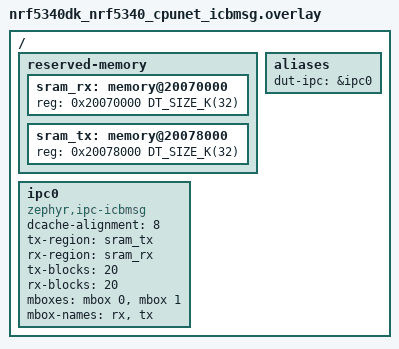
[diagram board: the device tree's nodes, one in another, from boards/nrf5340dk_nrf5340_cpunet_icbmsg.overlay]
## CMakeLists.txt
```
#
# Copyright (c) 2026 Nordic Semiconductor ASA
#
# SPDX-License-Identifier: Apache-2.0
#

cmake_minimum_required(VERSION 3.28.0)

find_package(Zephyr REQUIRED HINTS $ENV{ZEPHYR_BASE})
project(ipc_service_api_remote)

target_include_directories(app PRIVATE ${CMAKE_CURRENT_SOURCE_DIR}/../common)
target_sources(app PRIVATE src/remote.c)
```

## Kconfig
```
# Copyright (c) 2026 Nordic Semiconductor ASA
# SPDX-License-Identifier: Apache-2.0

rsource "../Kconfig"
```

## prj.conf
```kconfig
CONFIG_IPC_SERVICE=y
CONFIG_MBOX=y
CONFIG_LOG=y
```

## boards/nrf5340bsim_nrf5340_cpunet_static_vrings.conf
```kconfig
CONFIG_HEAP_MEM_POOL_SIZE=4096
CONFIG_OPENAMP=y
CONFIG_OPENAMP_MASTER=n
```

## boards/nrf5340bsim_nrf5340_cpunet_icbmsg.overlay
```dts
/*
 * Copyright (c) 2026 Nordic Semiconductor ASA
 *
 * SPDX-License-Identifier: Apache-2.0
 */

#include "nrf5340dk_nrf5340_cpunet_icbmsg.overlay"
```

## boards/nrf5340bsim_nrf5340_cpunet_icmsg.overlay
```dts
/*
 * Copyright (c) 2026 Nordic Semiconductor ASA
 *
 * SPDX-License-Identifier: Apache-2.0
 */

#include "nrf5340dk_nrf5340_cpunet_icmsg.overlay"
```

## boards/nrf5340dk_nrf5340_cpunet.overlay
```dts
/*
 * Copyright (c) 2026 Nordic Semiconductor ASA
 *
 * SPDX-License-Identifier: Apache-2.0
 */

#include "nrf5340dk_nrf5340_cpunet_common.dtsi"
```

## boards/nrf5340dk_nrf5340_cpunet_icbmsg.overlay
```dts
/*
 * Copyright (c) 2026 Nordic Semiconductor ASA
 *
 * SPDX-License-Identifier: Apache-2.0
 */

#include "nrf5340dk_nrf5340_cpunet_common.dtsi"

/ {
	reserved-memory {
		ranges;
		#address-cells = <1>;
		#size-cells = <1>;

		sram_rx: memory@20070000 {
			reg = <0x20070000 DT_SIZE_K(32)>;
		};

		sram_tx: memory@20078000 {
			reg = <0x20078000 DT_SIZE_K(32)>;
		};
	};

	ipc0: ipc0 {
		compatible = "zephyr,ipc-icbmsg";
		dcache-alignment = <8>;
		tx-region = <&sram_tx>;
		rx-region = <&sram_rx>;
		tx-blocks = <20>;
		rx-blocks = <20>;
		mboxes = <&mbox 0>, <&mbox 1>;
		mbox-names = "rx", "tx";
		status = "okay";
	};

	aliases {
		dut-ipc = &ipc0;
	};
};
```

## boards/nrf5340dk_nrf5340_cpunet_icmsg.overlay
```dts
/*
 * Copyright (c) 2026 Nordic Semiconductor ASA
 *
 * SPDX-License-Identifier: Apache-2.0
 */

#include "nrf5340dk_nrf5340_cpunet_common.dtsi"

/ {
	reserved-memory {
		ranges;
		#address-cells = <1>;
		#size-cells = <1>;

		sram_rx: memory@20070000 {
			reg = <0x20070000 DT_SIZE_K(32)>;
		};

		sram_tx: memory@20078000 {
			reg = <0x20078000 DT_SIZE_K(32)>;
		};
	};

	ipc0: ipc0 {
		compatible = "zephyr,ipc-icmsg";
		dcache-alignment = <8>;
		tx-region = <&sram_tx>;
		rx-region = <&sram_rx>;
		mboxes = <&mbox 0>, <&mbox 1>;
		mbox-names = "rx", "tx";
		status = "okay";
	};

	aliases {
		dut-ipc = &ipc0;
	};
};
```

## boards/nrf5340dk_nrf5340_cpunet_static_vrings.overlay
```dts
/*
 * Copyright (c) 2026 Nordic Semiconductor ASA
 *
 * SPDX-License-Identifier: Apache-2.0
 */

#include "nrf5340dk_nrf5340_cpunet_common.dtsi"
#include <zephyr/dt-bindings/ipc_service/static_vrings.h>

/ {
	reserved-memory {
		#address-cells = <1>;
		#size-cells = <1>;

		sram_ipc0: memory@20070000 {
			reg = <0x20070000 DT_SIZE_K(8)>;
		};
	};

	ipc0: ipc0 {
		compatible = "zephyr,ipc-openamp-static-vrings";
		memory-region = <&sram_ipc0>;
		mboxes = <&mbox 0>, <&mbox 1>;
		mbox-names = "rx", "tx";
		role = "remote";
		zephyr,buffer-size = <128>;
		status = "okay";
	};

	aliases {
		dut-ipc = &ipc0;
	};
};
```

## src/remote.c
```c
/*
 * Copyright (c) 2026 Nordic Semiconductor ASA
 *
 * SPDX-License-Identifier: Apache-2.0
 */

#include <string.h>

#include <zephyr/kernel.h>
#include <zephyr/device.h>
#include <zephyr/ipc/ipc_service.h>

#include <test_context.h>

#include <zephyr/logging/log.h>
LOG_MODULE_REGISTER(remote, LOG_LEVEL_INF);

#if DT_HAS_ALIAS(dut_ipc)
#define IPC_NODE DT_ALIAS(dut_ipc)
#elif DT_NUM_INST_STATUS_OKAY(zephyr_ipc_icbmsg) == 1
#define IPC_NODE DT_COMPAT_GET_ANY_STATUS_OKAY(zephyr_ipc_icbmsg)
#elif DT_NUM_INST_STATUS_OKAY(zephyr_ipc_icmsg) == 1
#define IPC_NODE DT_COMPAT_GET_ANY_STATUS_OKAY(zephyr_ipc_icmsg)
#elif DT_NUM_INST_STATUS_OKAY(zephyr_ipc_openamp_static_vrings) == 1
#define IPC_NODE DT_COMPAT_GET_ANY_STATUS_OKAY(zephyr_ipc_openamp_static_vrings)
#else
#error "No IPC node found"
#endif

static struct test_context test_ctx[TEST_EP_COUNT];
static const char *ep_name[TEST_EP_COUNT] = {"ep0", "ep1"};

static const struct device *ipc_instance = DEVICE_DT_GET(IPC_NODE);
static volatile bool close_after_unbound;

static volatile bool reregister_request;

static struct test_context *ep0(void)
{
	return &test_ctx[TEST_EP0];
}

static void reregister_action(struct test_context *ctx)
{
	int ret;

	ret = ipc_service_deregister_endpoint(&ctx->ep);
	if (ret < 0 && ret != -ENOENT) {
		LOG_ERR("ipc_service_deregister_endpoint() failed: %d", ret);
	}

	k_msleep(10);

	ret = ipc_service_register_endpoint(ipc_instance, &ctx->ep, &ctx->ep_cfg);
	if (ret < 0) {
		LOG_ERR("ipc_service_register_endpoint() after deregister failed: %d", ret);
	}
}

static void ep_bound(void *priv)
{
	struct test_context *ctx = priv;

	ctx->bound = true;
	LOG_INF("Endpoint bound");
}

static void ep_unbound(void *priv)
{
	struct test_context *ctx = priv;

	ctx->bound = false;
	ctx->unbound = true;
	LOG_INF("Endpoint unbound");

	reregister_request = true;
}

static void ep_error(const char *message, void *priv)
{
	ARG_UNUSED(priv);
	LOG_ERR("Endpoint error: %s", message);
}

static void ep_received(const void *data, size_t len, void *priv)
{
	const struct api_test_msg *msg = data;
	struct test_context *ctx = priv;
	struct api_test_msg rsp;
	int ret;

	if (len < sizeof(msg->cmd)) {
		LOG_ERR("Unexpected message size: %u", len);
		return;
	}

	switch (msg->cmd) {
	case API_TEST_CMD_PING:
		rsp.cmd = API_TEST_CMD_PONG;
		memset(rsp.data, 0, sizeof(rsp.data));
		ret = ipc_service_send(&ctx->ep, &rsp, sizeof(rsp));
		if (ret < 0) {
			LOG_ERR("PONG send failed: %d", ret);
		}
		break;
	case API_TEST_CMD_ECHO:
		if (len < sizeof(struct api_test_msg)) {
			LOG_ERR("ECHO message too short: %u", len);
			break;
		}
		rsp.cmd = API_TEST_CMD_ECHO_RSP;
		memcpy(rsp.data, msg->data, sizeof(rsp.data));
		ret = ipc_service_send(&ctx->ep, &rsp, sizeof(rsp));
		if (ret < 0) {
			LOG_ERR("ECHO_RSP send failed: %d", ret);
		}
		break;
	case API_TEST_CMD_DEREGISTER:
		reregister_request = true;
		break;
	default:
		LOG_ERR("Unhandled command: %u", msg->cmd);
		break;
	}
}

static int register_endpoint(struct test_context *ctx, const char *name, int priority)
{
	ctx->ep_cfg.name = name;
	ctx->ep_cfg.priv = ctx;
	ctx->ep_cfg.prio = priority;
	ctx->ep_cfg.cb.bound = ep_bound;
	ctx->ep_cfg.cb.unbound = ep_unbound;
	ctx->ep_cfg.cb.received = ep_received;
	ctx->ep_cfg.cb.error = ep_error;

	return ipc_service_register_endpoint(ipc_instance, &ctx->ep, &ctx->ep_cfg);
}

static void wait_for_bound(struct test_context *ctx)
{
	while (!wait_for_flag(&ctx->bound, 1000)) {
	}
}

int main(void)
{
	int ret;
	size_t ep_cnt = IS_ENABLED(CONFIG_IPC_SERVICE_API_TEST_SECOND_ENDPOINT) ? 2 : 1;

	ret = ipc_service_open_instance(ipc_instance);
	if (ret < 0 && ret != -EALREADY) {
		LOG_ERR("ipc_service_open_instance() failed: %d", ret);
		return ret;
	}

	for (size_t i = 0; i < ep_cnt; i++) {
		ret = register_endpoint(&test_ctx[i], ep_name[i], i);
		if (ret < 0) {
			LOG_ERR("ipc_service_register_endpoint() failed: %d", ret);
			return ret;
		}

		wait_for_bound(&test_ctx[i]);
	}

	LOG_INF("IPC service API remote ready");

	while (1) {
		k_msleep(1);

		if (reregister_request) {
			reregister_request = false;
			reregister_action(ep0());
		}
	}

	return 0;
}
```
